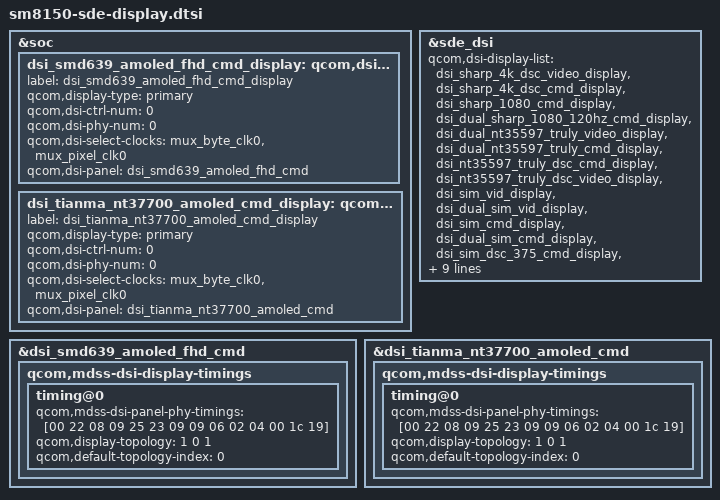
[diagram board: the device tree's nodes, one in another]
#include "dsi-panel-smd639-amoled-fhd-cmd.dtsi"
#include "dsi-panel-tianma-nt37700-amoled-cmd.dtsi"


&soc {

	dsi_smd639_amoled_fhd_cmd_display: qcom,dsi-display@23 {
                label = "dsi_smd639_amoled_fhd_cmd_display";
                qcom,display-type = "primary";

                qcom,dsi-ctrl-num = <0>;
                qcom,dsi-phy-num = <0>;
                qcom,dsi-select-clocks =  "mux_byte_clk0", "mux_pixel_clk0";

                qcom,dsi-panel = <&dsi_smd639_amoled_fhd_cmd>;
        };

        dsi_tianma_nt37700_amoled_cmd_display: qcom,dsi-display@24 {
                label = "dsi_tianma_nt37700_amoled_cmd_display";
                qcom,display-type = "primary";

                qcom,dsi-ctrl-num = <0>;
                qcom,dsi-phy-num = <0>;
                qcom,dsi-select-clocks =  "mux_byte_clk0", "mux_pixel_clk0";

                qcom,dsi-panel = <&dsi_tianma_nt37700_amoled_cmd>;
        };

        
};


&sde_dsi {
	qcom,dsi-display-list =
                        <&dsi_sharp_4k_dsc_video_display
                        &dsi_sharp_4k_dsc_cmd_display
                        &dsi_sharp_1080_cmd_display
                        &dsi_dual_sharp_1080_120hz_cmd_display
                        &dsi_dual_nt35597_truly_video_display
                        &dsi_dual_nt35597_truly_cmd_display
                        &dsi_nt35597_truly_dsc_cmd_display
                        &dsi_nt35597_truly_dsc_video_display
                        &dsi_sim_vid_display
                        &dsi_dual_sim_vid_display
                        &dsi_sim_cmd_display
                        &dsi_dual_sim_cmd_display
                        &dsi_sim_dsc_375_cmd_display
                        &dsi_dual_sim_dsc_375_cmd_display
                        &dsi_sw43404_amoled_cmd_display
                        &dsi_nt35695b_truly_fhd_cmd_display
                        &dsi_nt35695b_truly_fhd_video_display
                        &dsi_sw43404_amoled_video_display
                        &dsi_smd639_amoled_fhd_cmd_display
                        &dsi_tianma_nt37700_amoled_cmd_display
                        &dsi_sw43404_amoled_fhd_plus_cmd_display
                        &dsi_dual_nt36850_truly_cmd_display>;
};

&dsi_smd639_amoled_fhd_cmd {
        qcom,mdss-dsi-display-timings {
                timing@0 {
                        qcom,mdss-dsi-panel-phy-timings = [00 22 08 09 25 23 09
                                09 06 02 04 00 1c 19];
                        qcom,display-topology = <1 0 1>;
                        qcom,default-topology-index = <0>;
                };
        };
};

&dsi_tianma_nt37700_amoled_cmd {
        qcom,mdss-dsi-display-timings {
                timing@0 {
                        qcom,mdss-dsi-panel-phy-timings = [00 22 08 09 25 23 09
                                09 06 02 04 00 1c 19];
                        qcom,display-topology = <1 0 1>;
                        qcom,default-topology-index = <0>;
                };
        };
};
